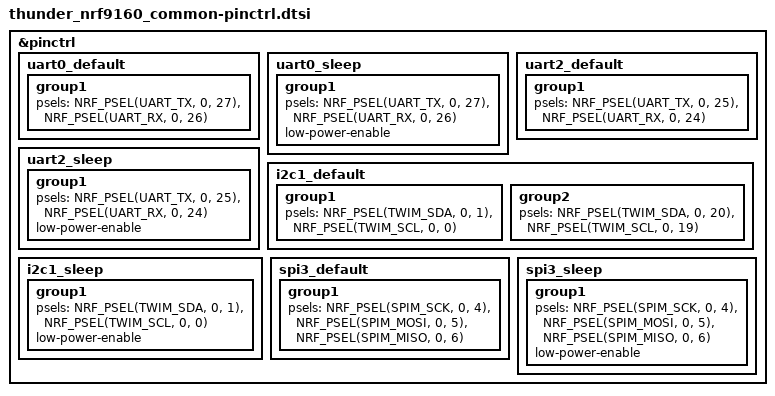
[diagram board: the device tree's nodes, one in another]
/*
 * Copyright (c) 2018-2020 Nordic Semiconductor ASA
 *
 * SPDX-License-Identifier: Apache-2.0
 */

&pinctrl {
	uart0_default: uart0_default {
		group1 {
			psels = <NRF_PSEL(UART_TX, 0, 27)>,
				<NRF_PSEL(UART_RX, 0, 26)>;
		};
	};

	uart0_sleep: uart0_sleep {
		group1 {
			psels = <NRF_PSEL(UART_TX, 0, 27)>,
				<NRF_PSEL(UART_RX, 0, 26)>;
			low-power-enable;
		};
	};

	uart2_default: uart2_default {
		group1 {
			psels = <NRF_PSEL(UART_TX, 0, 25)>,
				<NRF_PSEL(UART_RX, 0, 24)>;
		};
	};

	uart2_sleep: uart2_sleep {
		group1 {
			psels = <NRF_PSEL(UART_TX, 0, 25)>,
				<NRF_PSEL(UART_RX, 0, 24)>;
			low-power-enable;
		};
	};

	i2c1_default: i2c1_default {
		group1 {
			psels = <NRF_PSEL(TWIM_SDA, 0, 1)>,
				<NRF_PSEL(TWIM_SCL, 0, 0)>;
		};

		group2 {
			psels = <NRF_PSEL(TWIM_SDA, 0, 20)>,
				<NRF_PSEL(TWIM_SCL, 0, 19)>;
		};
	};


	i2c1_sleep: i2c1_sleep {
		group1 {
			psels = <NRF_PSEL(TWIM_SDA, 0, 1)>,
				<NRF_PSEL(TWIM_SCL, 0, 0)>;
			low-power-enable;
		};
	};

	spi3_default: spi3_default {
		group1 {
			psels = <NRF_PSEL(SPIM_SCK, 0, 4)>,
				<NRF_PSEL(SPIM_MOSI, 0, 5)>,
				<NRF_PSEL(SPIM_MISO, 0, 6)>;
		};
	};

	spi3_sleep: spi3_sleep {
		group1 {
			psels = <NRF_PSEL(SPIM_SCK, 0, 4)>,
				<NRF_PSEL(SPIM_MOSI, 0, 5)>,
				<NRF_PSEL(SPIM_MISO, 0, 6)>;
			low-power-enable;
		};
	};

};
